VERSION ""

NS_ :

BS_:

BU_: Vector__XXX

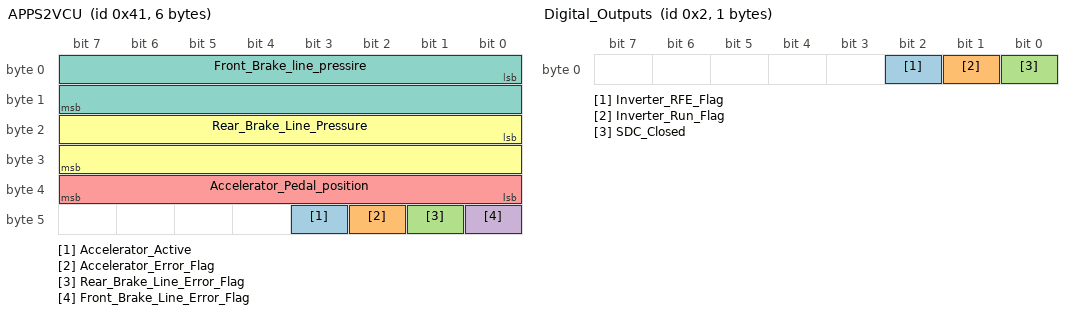
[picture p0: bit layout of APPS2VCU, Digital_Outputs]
BO_ 65 APPS2VCU: 6 Vector__XXX
SG_ Accelerator_Active : 43|1@1+ (1,0) [0|1] "" Vector__XXX
SG_ Accelerator_Error_Flag : 42|1@1+ (1,0) [0|1] "" Vector__XXX
SG_ Rear_Brake_Line_Error_Flag : 41|1@1+ (1,0) [0|1] "" Vector__XXX
SG_ Front_Brake_Line_Error_Flag : 40|1@1+ (1,0) [0|1] "" Vector__XXX
SG_ Accelerator_Pedal_position : 32|8@1+ (1,0) [0|255] "%" Vector__XXX
SG_ Rear_Brake_Line_Pressure : 16|16@1+ (1,0) [0|65535] "bar" Vector__XXX
SG_ Front_Brake_line_pressire : 0|16@1+ (1,0) [0|32767] "bar" Vector__XXX

BO_ 3 VCU_status: 1 Vector__XXX
SG_ EV_STATE : 0|3@1+ (1,0) [0|7] "" Vector__XXX

BO_ 513 Inverter_Snd: 4 Vector__XXX
SG_ Inverter_Snd_Mux M : 0|8@1+ (1,0) [0|0] "" Vector__XXX
SG_ Speed_Request m49 : 8|8@1- (1,0) [-128|127] "" Vector__XXX
SG_ Torque_Request m144 : 8|8@1- (1,0) [-128|127] "" Vector__XXX
SG_ Set_kern_mode m81 : 8|8@1- (1,0) [-128|127] "" Vector__XXX
SG_ Read_cmd m61 : 8|8@1- (1,0) [-128|127] "" Vector__XXX

BO_ 385 Inveter_Rcv: 4 Vector__XXX
SG_ Inveter_Rcv_Mux M : 0|8@1+ (1,0) [0|0] "" Vector__XXX
SG_ Actual_Torque m160 : 8|8@1- (1,0) [-128|127] "" Vector__XXX
SG_ IO_Bitmap m216 : 8|16@1- (1,0) [-32768|32767] "" Vector__XXX
SG_ GO_Drive_Enabled m227 : 8|1@1+ (1,0) [0|1] "" Vector__XXX
SG_ RDY m226 : 8|1@1+ (1,0) [0|1] "" Vector__XXX
SG_ RUN m232 : 8|1@1+ (1,0) [0|1] "" Vector__XXX
SG_ N_Actual m48 : 8|16@1- (1,0) [0|255] "" Vector__XXX
SG_ Kern_Mode m81 : 8|8@1- (1,0) [-128|127] "" Vector__XXX

BO_ 2 Digital_Outputs: 1 Vector__XXX
SG_ Inverter_RFE_Flag : 2|1@1+ (1,0) [0|1] "" Vector__XXX
SG_ Inverter_Run_Flag : 1|1@1+ (1,0) [0|1] "" Vector__XXX
SG_ SDC_Closed : 0|1@1+ (1,0) [0|1] "" Vector__XXX

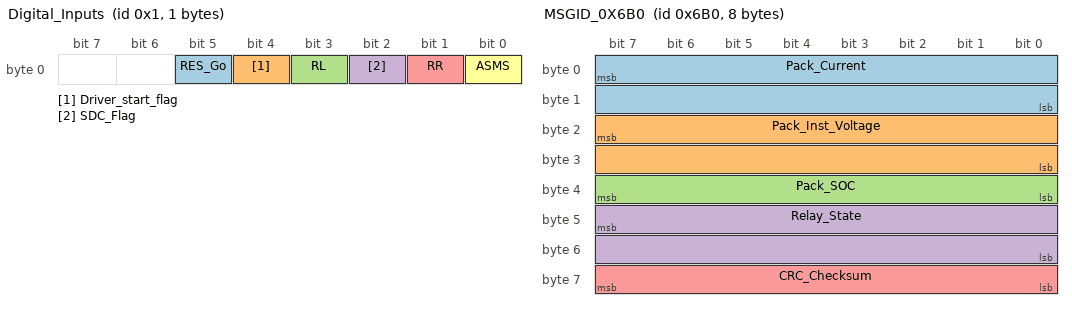
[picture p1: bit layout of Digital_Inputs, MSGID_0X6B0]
BO_ 1 Digital_Inputs: 1 Vector__XXX
SG_ RES_Go : 5|1@1+ (1,0) [0|1] "" Vector__XXX
SG_ Driver_start_flag : 4|1@1+ (1,0) [0|1] "" Vector__XXX
SG_ RL : 3|1@1+ (1,0) [0|1] "" Vector__XXX
SG_ SDC_Flag : 2|1@1+ (1,0) [0|1] "" Vector__XXX
SG_ RR : 1|1@1+ (1,0) [0|1] "" Vector__XXX
SG_ ASMS : 0|1@1+ (1,0) [0|1] "" Vector__XXX

BO_ 1712 MSGID_0X6B0: 8 Vector__XXX
SG_ Pack_Current : 7|16@0+ (0.1,0) [0|6553.5] "Amps" Vector__XXX
SG_ Pack_Inst_Voltage : 23|16@0+ (0.1,0) [0|6553.5] "Volts" Vector__XXX
SG_ Pack_SOC : 39|8@0+ (0.5,0) [0|127.5] "Percent" Vector__XXX
SG_ Relay_State : 47|16@0+ (1,0) [0|65535] "" Vector__XXX
SG_ CRC_Checksum : 63|8@0+ (1,1720) [1720|1720] "" Vector__XXX

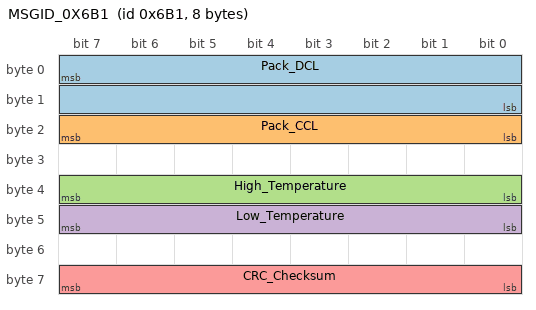
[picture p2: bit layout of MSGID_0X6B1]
BO_ 1713 MSGID_0X6B1: 8 Vector__XXX
SG_ Pack_DCL : 7|16@0+ (1,0) [0|65535] "Amps" Vector__XXX
SG_ Pack_CCL : 23|8@0+ (1,0) [0|255] "Amps" Vector__XXX
SG_ High_Temperature : 39|8@0+ (1,0) [0|255] "Celsius" Vector__XXX
SG_ Low_Temperature : 47|8@0+ (1,0) [0|255] "Celsius" Vector__XXX
SG_ CRC_Checksum : 63|8@0+ (1,1721) [1721|1721] "" Vector__XXX

BO_ 84 VCU2AI_status: 1 Vector__XXX
SG_ AS_STATE : 0|3@1+ (1,0) [0|7] "" Vector__XXX

CM_ BO_ 1712 "This ID Transmits at 8 ms.";
CM_ BO_ 1713 "This ID Transmits at 104 ms.";

BA_DEF_  "BusType" STRING ;
BA_DEF_ SG_  "GenSigStartValue" FLOAT -3.4E+038 3.4E+038;

BA_DEF_DEF_  "BusType" "CAN";
BA_DEF_DEF_  "GenSigStartValue" 0;

BA_ "GenSigStartValue" SG_ 1712 CRC_Checksum 1720;
BA_ "GenSigStartValue" SG_ 1713 CRC_Checksum 1721;

VAL_ 513 Inverter_Snd_Mux 49 "Send_mux_49" 144 "Send_mux_144" 81 "Send_mux_81" 61 "Send_mux_61";
VAL_ 385 Inveter_Rcv_Mux 160 "Inv_Rcv_Mux_160" 216 "Inv_Rcv_Mux_216" 227 "Inv_Rcv_Mux_227" 226 "Inv_Rcv_Mux_226" 232 "Inv_Rcv_Mux_232" 48 "Inv_Rcv_Mux_48" 81 "Inv_Rcv_Mux_81";
VAL_ 3 EV_STATE 1 "TS_OFF" 2 "TS_ACTIVE" 3 "MANUAL_DRIVING" 7 "CORSA_MODE";
VAL_ 84 AS_STATE 1 "OFF" 2 "READY" 3 "DRIVING" 4 "EMERGENCY" 5 "FINISHED" 6 "MANUAL_DRIVING";
